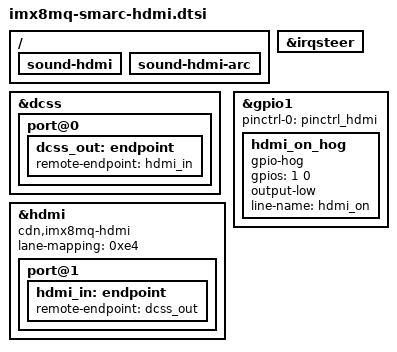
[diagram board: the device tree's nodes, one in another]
// SPDX-License-Identifier: (GPL-2.0 OR MIT)
/*
 * Copyright 2017 NXP
 * Copyright 2020 Embedian, Inc.
 * Copyright (C) 2017-2018 Pengutronix, Lucas Stach <kernel@pengutronix.de>
 */

/ {
        sound-hdmi {
        	status = "okay";
	};

        sound-hdmi-arc {
        	status = "okay";
        };
};

&irqsteer {
        status = "okay";
};

&dcss {
        status = "okay";

        port@0 {
                dcss_out: endpoint {
                          remote-endpoint = <&hdmi_in>;
                };
        };
};

&hdmi {
        compatible = "cdn,imx8mq-hdmi";
        lane-mapping = <0xe4>;
        status = "okay";
        port@1 {
                hdmi_in: endpoint {
                        remote-endpoint = <&dcss_out>;
                };
        };
};

&gpio1 {
	pinctrl-names = "default";
	pinctrl-0 = <&pinctrl_hdmi>;

	hdmi_on_hog {
		gpio-hog;
		gpios = <1 0>;
		output-low;
		line-name = "hdmi_on";
	};
};
